AUTOSAR XML (schema 00047)
package /LIN2
  n pdu NPdu_LIN2_MasterReq
  n pdu NPdu_LIN2_SlaveResp
package /LIN2/CLUSTERS
  lin cluster LIN2: protocol-version="2.1", speed=19200
    lin physical channel PhysicalChannel_0: comm-connectors=Conn_ECU1_LIN2
      frame LinUnconditionalFrame_LIN2_Master_Cmd: id 0x8, frame-length=5
        pdu ISignalIPdu_LIN2_Master_Cmd: length=5
          signal ISignal_LIN2_Master_Cmd_NAD: start 0, 8 bit, little-endian, init-value=255
          signal ISignal_LIN2_Master_Cmd_PCI_Type: start 8, 8 bit, little-endian, init-value=3
          signal ISignal_LIN2_Master_Cmd_SID: start 16, 8 bit, little-endian, init-value=0
          signal ISignal_LIN2_Master_Cmd_RL_Sensor_Tx: start 24, 1 bit, little-endian, init-value=0
          signal ISignal_LIN2_Master_Cmd_RCL_Sensor_Tx: start 25, 1 bit, little-endian, init-value=0
          signal ISignal_LIN2_Master_Cmd_RCR_Sensor_Tx: start 26, 1 bit, little-endian, init-value=0
          signal ISignal_LIN2_Master_Cmd_RR_Sensor_Tx: start 27, 1 bit, little-endian, init-value=0
          signal ISignal_LIN2_Master_Cmd_FL_Sensor_Tx: start 28, 1 bit, little-endian, init-value=0
          signal ISignal_LIN2_Master_Cmd_FCL_Sensor_Tx: start 29, 1 bit, little-endian, init-value=0
          signal ISignal_LIN2_Master_Cmd_FCR_Sensor_Tx: start 30, 1 bit, little-endian, init-value=0
          signal ISignal_LIN2_Master_Cmd_FR_Sensor_Tx: start 31, 1 bit, little-endian, init-value=0
          signal ISignal_LIN2_Master_Cmd_RL_Sensor_Rx: start 32, 1 bit, little-endian, init-value=0
          signal ISignal_LIN2_Master_Cmd_RCL_Sensor_Rx: start 33, 1 bit, little-endian, init-value=0
          signal ISignal_LIN2_Master_Cmd_RCR_Sensor_Rx: start 34, 1 bit, little-endian, init-value=0
          signal ISignal_LIN2_Master_Cmd_RR_Sensor_Rx: start 35, 1 bit, little-endian, init-value=0
          signal ISignal_LIN2_Master_Cmd_FL_Sensor_Rx: start 36, 1 bit, little-endian, init-value=0
          signal ISignal_LIN2_Master_Cmd_FCL_Sensor_Rx: start 37, 1 bit, little-endian, init-value=0
          signal ISignal_LIN2_Master_Cmd_FCR_Sensor_Rx: start 38, 1 bit, little-endian, init-value=0
          signal ISignal_LIN2_Master_Cmd_FR_Sensor_Rx: start 39, 1 bit, little-endian, init-value=0
          mapping SigGrp_LIN2_Master_Cmd: i-signal-group=MsgGr_LIN2_Master_Cmd
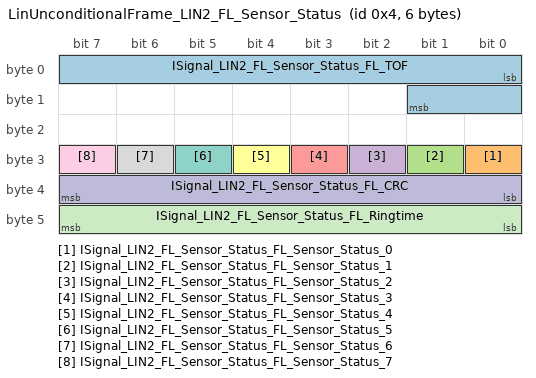
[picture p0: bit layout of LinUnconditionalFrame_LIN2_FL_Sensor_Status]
      frame LinUnconditionalFrame_LIN2_FL_Sensor_Status: id 0x4, frame-length=6
        pdu ISignalIPdu_LIN2_FL_Sensor_Status: length=6
          signal ISignal_LIN2_FL_Sensor_Status_FL_TOF: start 0, 10 bit, little-endian, init-value=0
          signal ISignal_LIN2_FL_Sensor_Status_FL_Sensor_Status_0: start 24, 1 bit, little-endian, init-value=0
          signal ISignal_LIN2_FL_Sensor_Status_FL_Sensor_Status_1: start 25, 1 bit, little-endian, init-value=0
          signal ISignal_LIN2_FL_Sensor_Status_FL_Sensor_Status_2: start 26, 1 bit, little-endian, init-value=0
          signal ISignal_LIN2_FL_Sensor_Status_FL_Sensor_Status_3: start 27, 1 bit, little-endian, init-value=0
          signal ISignal_LIN2_FL_Sensor_Status_FL_Sensor_Status_4: start 28, 1 bit, little-endian, init-value=0
          signal ISignal_LIN2_FL_Sensor_Status_FL_Sensor_Status_5: start 29, 1 bit, little-endian, init-value=0
          signal ISignal_LIN2_FL_Sensor_Status_FL_Sensor_Status_6: start 30, 1 bit, little-endian, init-value=0
          signal ISignal_LIN2_FL_Sensor_Status_FL_Sensor_Status_7: start 31, 1 bit, little-endian, init-value=0
          signal ISignal_LIN2_FL_Sensor_Status_FL_CRC: start 32, 8 bit, little-endian, init-value=0
          signal ISignal_LIN2_FL_Sensor_Status_FL_Ringtime: start 40, 8 bit, little-endian, init-value=0
          mapping SigGrp_LIN2_FL_Sensor_Status: i-signal-group=MsgGr_LIN2_FL_Sensor_Status
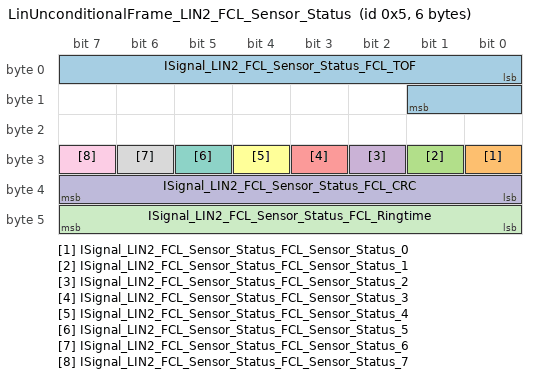
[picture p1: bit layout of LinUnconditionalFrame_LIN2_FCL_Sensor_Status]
      frame LinUnconditionalFrame_LIN2_FCL_Sensor_Status: id 0x5, frame-length=6
        pdu ISignalIPdu_LIN2_FCL_Sensor_Status: length=6
          signal ISignal_LIN2_FCL_Sensor_Status_FCL_TOF: start 0, 10 bit, little-endian, init-value=0
          signal ISignal_LIN2_FCL_Sensor_Status_FCL_Sensor_Status_0: start 24, 1 bit, little-endian, init-value=0
          signal ISignal_LIN2_FCL_Sensor_Status_FCL_Sensor_Status_1: start 25, 1 bit, little-endian, init-value=0
          signal ISignal_LIN2_FCL_Sensor_Status_FCL_Sensor_Status_2: start 26, 1 bit, little-endian, init-value=0
          signal ISignal_LIN2_FCL_Sensor_Status_FCL_Sensor_Status_3: start 27, 1 bit, little-endian, init-value=0
          signal ISignal_LIN2_FCL_Sensor_Status_FCL_Sensor_Status_4: start 28, 1 bit, little-endian, init-value=0
          signal ISignal_LIN2_FCL_Sensor_Status_FCL_Sensor_Status_5: start 29, 1 bit, little-endian, init-value=0
          signal ISignal_LIN2_FCL_Sensor_Status_FCL_Sensor_Status_6: start 30, 1 bit, little-endian, init-value=0
          signal ISignal_LIN2_FCL_Sensor_Status_FCL_Sensor_Status_7: start 31, 1 bit, little-endian, init-value=0
          signal ISignal_LIN2_FCL_Sensor_Status_FCL_CRC: start 32, 8 bit, little-endian, init-value=0
          signal ISignal_LIN2_FCL_Sensor_Status_FCL_Ringtime: start 40, 8 bit, little-endian, init-value=0
          mapping SigGrp_LIN2_FCL_Sensor_Status: i-signal-group=MsgGr_LIN2_FCL_Sensor_Status
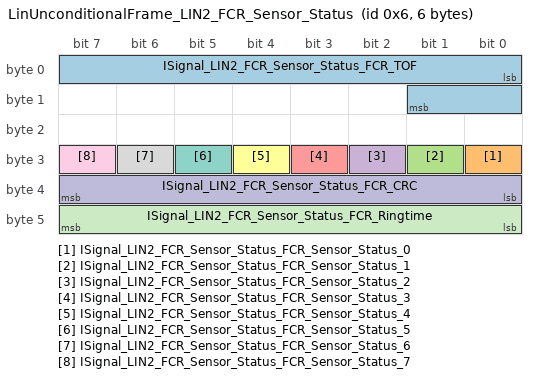
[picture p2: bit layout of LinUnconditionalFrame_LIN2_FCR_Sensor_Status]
      frame LinUnconditionalFrame_LIN2_FCR_Sensor_Status: id 0x6, frame-length=6
        pdu ISignalIPdu_LIN2_FCR_Sensor_Status: length=6
          signal ISignal_LIN2_FCR_Sensor_Status_FCR_TOF: start 0, 10 bit, little-endian, init-value=0
          signal ISignal_LIN2_FCR_Sensor_Status_FCR_Sensor_Status_0: start 24, 1 bit, little-endian, init-value=0
          signal ISignal_LIN2_FCR_Sensor_Status_FCR_Sensor_Status_1: start 25, 1 bit, little-endian, init-value=0
          signal ISignal_LIN2_FCR_Sensor_Status_FCR_Sensor_Status_2: start 26, 1 bit, little-endian, init-value=0
          signal ISignal_LIN2_FCR_Sensor_Status_FCR_Sensor_Status_3: start 27, 1 bit, little-endian, init-value=0
          signal ISignal_LIN2_FCR_Sensor_Status_FCR_Sensor_Status_4: start 28, 1 bit, little-endian, init-value=0
          signal ISignal_LIN2_FCR_Sensor_Status_FCR_Sensor_Status_5: start 29, 1 bit, little-endian, init-value=0
          signal ISignal_LIN2_FCR_Sensor_Status_FCR_Sensor_Status_6: start 30, 1 bit, little-endian, init-value=0
          signal ISignal_LIN2_FCR_Sensor_Status_FCR_Sensor_Status_7: start 31, 1 bit, little-endian, init-value=0
          signal ISignal_LIN2_FCR_Sensor_Status_FCR_CRC: start 32, 8 bit, little-endian, init-value=0
          signal ISignal_LIN2_FCR_Sensor_Status_FCR_Ringtime: start 40, 8 bit, little-endian, init-value=0
          mapping SigGrp_LIN2_FCR_Sensor_Status: i-signal-group=MsgGr_LIN2_FCR_Sensor_Status
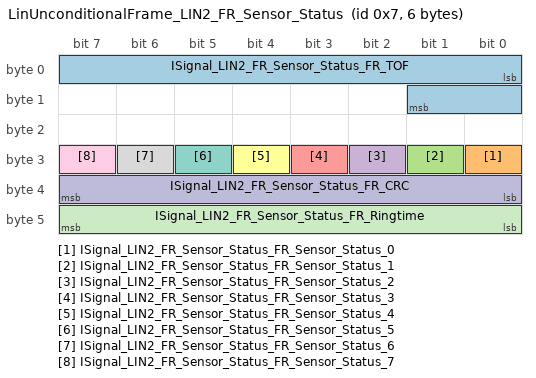
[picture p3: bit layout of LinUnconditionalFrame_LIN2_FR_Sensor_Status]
      frame LinUnconditionalFrame_LIN2_FR_Sensor_Status: id 0x7, frame-length=6
        pdu ISignalIPdu_LIN2_FR_Sensor_Status: length=6
          signal ISignal_LIN2_FR_Sensor_Status_FR_TOF: start 0, 10 bit, little-endian, init-value=0
          signal ISignal_LIN2_FR_Sensor_Status_FR_Sensor_Status_0: start 24, 1 bit, little-endian, init-value=0
          signal ISignal_LIN2_FR_Sensor_Status_FR_Sensor_Status_1: start 25, 1 bit, little-endian, init-value=0
          signal ISignal_LIN2_FR_Sensor_Status_FR_Sensor_Status_2: start 26, 1 bit, little-endian, init-value=0
          signal ISignal_LIN2_FR_Sensor_Status_FR_Sensor_Status_3: start 27, 1 bit, little-endian, init-value=0
          signal ISignal_LIN2_FR_Sensor_Status_FR_Sensor_Status_4: start 28, 1 bit, little-endian, init-value=0
          signal ISignal_LIN2_FR_Sensor_Status_FR_Sensor_Status_5: start 29, 1 bit, little-endian, init-value=0
          signal ISignal_LIN2_FR_Sensor_Status_FR_Sensor_Status_6: start 30, 1 bit, little-endian, init-value=0
          signal ISignal_LIN2_FR_Sensor_Status_FR_Sensor_Status_7: start 31, 1 bit, little-endian, init-value=0
          signal ISignal_LIN2_FR_Sensor_Status_FR_CRC: start 32, 8 bit, little-endian, init-value=0
          signal ISignal_LIN2_FR_Sensor_Status_FR_Ringtime: start 40, 8 bit, little-endian, init-value=0
          mapping SigGrp_LIN2_FR_Sensor_Status: i-signal-group=MsgGr_LIN2_FR_Sensor_Status
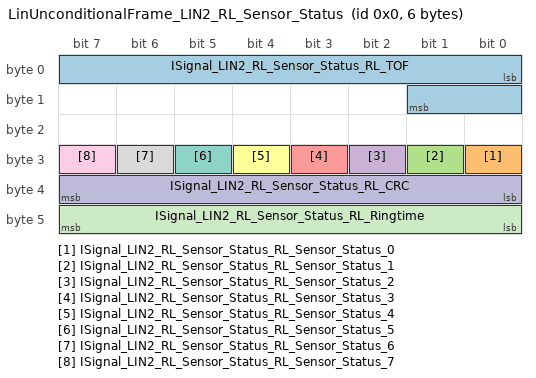
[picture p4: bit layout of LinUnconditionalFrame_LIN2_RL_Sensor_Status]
      frame LinUnconditionalFrame_LIN2_RL_Sensor_Status: id 0x0, frame-length=6
        pdu ISignalIPdu_LIN2_RL_Sensor_Status: length=6
          signal ISignal_LIN2_RL_Sensor_Status_RL_TOF: start 0, 10 bit, little-endian, init-value=0
          signal ISignal_LIN2_RL_Sensor_Status_RL_Sensor_Status_0: start 24, 1 bit, little-endian, init-value=0
          signal ISignal_LIN2_RL_Sensor_Status_RL_Sensor_Status_1: start 25, 1 bit, little-endian, init-value=0
          signal ISignal_LIN2_RL_Sensor_Status_RL_Sensor_Status_2: start 26, 1 bit, little-endian, init-value=0
          signal ISignal_LIN2_RL_Sensor_Status_RL_Sensor_Status_3: start 27, 1 bit, little-endian, init-value=0
          signal ISignal_LIN2_RL_Sensor_Status_RL_Sensor_Status_4: start 28, 1 bit, little-endian, init-value=0
          signal ISignal_LIN2_RL_Sensor_Status_RL_Sensor_Status_5: start 29, 1 bit, little-endian, init-value=0
          signal ISignal_LIN2_RL_Sensor_Status_RL_Sensor_Status_6: start 30, 1 bit, little-endian, init-value=0
          signal ISignal_LIN2_RL_Sensor_Status_RL_Sensor_Status_7: start 31, 1 bit, little-endian, init-value=0
          signal ISignal_LIN2_RL_Sensor_Status_RL_CRC: start 32, 8 bit, little-endian, init-value=0
          signal ISignal_LIN2_RL_Sensor_Status_RL_Ringtime: start 40, 8 bit, little-endian, init-value=0
          mapping SigGrp_LIN2_RL_Sensor_Status: i-signal-group=MsgGr_LIN2_RL_Sensor_Status
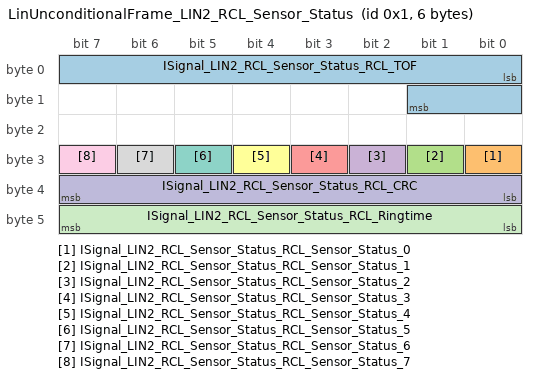
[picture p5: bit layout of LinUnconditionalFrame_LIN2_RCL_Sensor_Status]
      frame LinUnconditionalFrame_LIN2_RCL_Sensor_Status: id 0x1, frame-length=6
        pdu ISignalIPdu_LIN2_RCL_Sensor_Status: length=6
          signal ISignal_LIN2_RCL_Sensor_Status_RCL_TOF: start 0, 10 bit, little-endian, init-value=0
          signal ISignal_LIN2_RCL_Sensor_Status_RCL_Sensor_Status_0: start 24, 1 bit, little-endian, init-value=0
          signal ISignal_LIN2_RCL_Sensor_Status_RCL_Sensor_Status_1: start 25, 1 bit, little-endian, init-value=0
          signal ISignal_LIN2_RCL_Sensor_Status_RCL_Sensor_Status_2: start 26, 1 bit, little-endian, init-value=0
          signal ISignal_LIN2_RCL_Sensor_Status_RCL_Sensor_Status_3: start 27, 1 bit, little-endian, init-value=0
          signal ISignal_LIN2_RCL_Sensor_Status_RCL_Sensor_Status_4: start 28, 1 bit, little-endian, init-value=0
          signal ISignal_LIN2_RCL_Sensor_Status_RCL_Sensor_Status_5: start 29, 1 bit, little-endian, init-value=0
          signal ISignal_LIN2_RCL_Sensor_Status_RCL_Sensor_Status_6: start 30, 1 bit, little-endian, init-value=0
          signal ISignal_LIN2_RCL_Sensor_Status_RCL_Sensor_Status_7: start 31, 1 bit, little-endian, init-value=0
          signal ISignal_LIN2_RCL_Sensor_Status_RCL_CRC: start 32, 8 bit, little-endian, init-value=0
          signal ISignal_LIN2_RCL_Sensor_Status_RCL_Ringtime: start 40, 8 bit, little-endian, init-value=0
          mapping SigGrp_LIN2_RCL_Sensor_Status: i-signal-group=MsgGr_LIN2_RCL_Sensor_Status
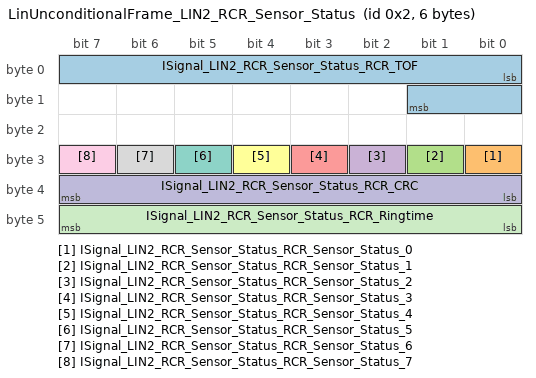
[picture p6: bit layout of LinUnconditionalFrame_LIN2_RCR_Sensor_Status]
      frame LinUnconditionalFrame_LIN2_RCR_Sensor_Status: id 0x2, frame-length=6
        pdu ISignalIPdu_LIN2_RCR_Sensor_Status: length=6
          signal ISignal_LIN2_RCR_Sensor_Status_RCR_TOF: start 0, 10 bit, little-endian, init-value=0
          signal ISignal_LIN2_RCR_Sensor_Status_RCR_Sensor_Status_0: start 24, 1 bit, little-endian, init-value=0
          signal ISignal_LIN2_RCR_Sensor_Status_RCR_Sensor_Status_1: start 25, 1 bit, little-endian, init-value=0
          signal ISignal_LIN2_RCR_Sensor_Status_RCR_Sensor_Status_2: start 26, 1 bit, little-endian, init-value=0
          signal ISignal_LIN2_RCR_Sensor_Status_RCR_Sensor_Status_3: start 27, 1 bit, little-endian, init-value=0
          signal ISignal_LIN2_RCR_Sensor_Status_RCR_Sensor_Status_4: start 28, 1 bit, little-endian, init-value=0
          signal ISignal_LIN2_RCR_Sensor_Status_RCR_Sensor_Status_5: start 29, 1 bit, little-endian, init-value=0
          signal ISignal_LIN2_RCR_Sensor_Status_RCR_Sensor_Status_6: start 30, 1 bit, little-endian, init-value=0
          signal ISignal_LIN2_RCR_Sensor_Status_RCR_Sensor_Status_7: start 31, 1 bit, little-endian, init-value=0
          signal ISignal_LIN2_RCR_Sensor_Status_RCR_CRC: start 32, 8 bit, little-endian, init-value=0
          signal ISignal_LIN2_RCR_Sensor_Status_RCR_Ringtime: start 40, 8 bit, little-endian, init-value=0
          mapping SigGrp_LIN2_RCR_Sensor_Status: i-signal-group=MsgGr_LIN2_RCR_Sensor_Status
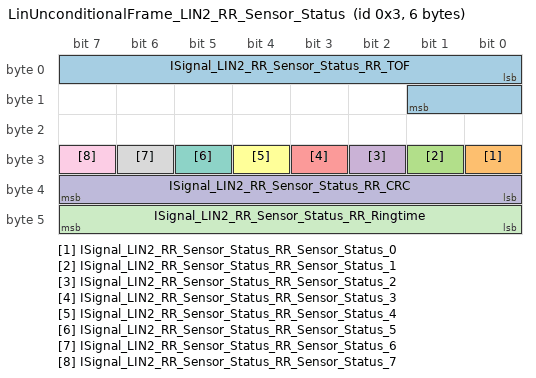
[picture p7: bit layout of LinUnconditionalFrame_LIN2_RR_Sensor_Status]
      frame LinUnconditionalFrame_LIN2_RR_Sensor_Status: id 0x3, frame-length=6
        pdu ISignalIPdu_LIN2_RR_Sensor_Status: length=6
          signal ISignal_LIN2_RR_Sensor_Status_RR_TOF: start 0, 10 bit, little-endian, init-value=0
          signal ISignal_LIN2_RR_Sensor_Status_RR_Sensor_Status_0: start 24, 1 bit, little-endian, init-value=0
          signal ISignal_LIN2_RR_Sensor_Status_RR_Sensor_Status_1: start 25, 1 bit, little-endian, init-value=0
          signal ISignal_LIN2_RR_Sensor_Status_RR_Sensor_Status_2: start 26, 1 bit, little-endian, init-value=0
          signal ISignal_LIN2_RR_Sensor_Status_RR_Sensor_Status_3: start 27, 1 bit, little-endian, init-value=0
          signal ISignal_LIN2_RR_Sensor_Status_RR_Sensor_Status_4: start 28, 1 bit, little-endian, init-value=0
          signal ISignal_LIN2_RR_Sensor_Status_RR_Sensor_Status_5: start 29, 1 bit, little-endian, init-value=0
          signal ISignal_LIN2_RR_Sensor_Status_RR_Sensor_Status_6: start 30, 1 bit, little-endian, init-value=0
          signal ISignal_LIN2_RR_Sensor_Status_RR_Sensor_Status_7: start 31, 1 bit, little-endian, init-value=0
          signal ISignal_LIN2_RR_Sensor_Status_RR_CRC: start 32, 8 bit, little-endian, init-value=0
          signal ISignal_LIN2_RR_Sensor_Status_RR_Ringtime: start 40, 8 bit, little-endian, init-value=0
          mapping SigGrp_LIN2_RR_Sensor_Status: i-signal-group=MsgGr_LIN2_RR_Sensor_Status
      frame LinUnconditionalFrame_LIN2_MasterReq: id 0x3C, frame-length=8, lin-checksum=CLASSIC
        dcm i pdu DcmIPdu_LIN2_MasterReq: length=8, diag-pdu-type=DIAG-REQUEST
      frame LinUnconditionalFrame_LIN2_SlaveResp: id 0x3D, frame-length=8, lin-checksum=CLASSIC
        dcm i pdu DcmIPdu_LIN2_SlaveResp: length=8, diag-pdu-type=DIAG-RESPONSE
      22 x lin schedule table, all with run-mode=RUN-CONTINUOUS:
        LinScheduleTable_SCHEDULER_RPAS_NORMAL
          table-entrys:
            delay=0.08, position-in-table=0, frame-triggering=LinFrameTriggering_LIN2_Master_Cmd
            delay=0.01, position-in-table=1, frame-triggering=LinFrameTriggering_LIN2_RL_Sensor_Status
            delay=0.08, position-in-table=2, frame-triggering=LinFrameTriggering_LIN2_Master_Cmd
            delay=0.01, position-in-table=3, frame-triggering=LinFrameTriggering_LIN2_RR_Sensor_Status
            delay=0.08, position-in-table=4, frame-triggering=LinFrameTriggering_LIN2_Master_Cmd
            delay=0.01, position-in-table=5, frame-triggering=LinFrameTriggering_LIN2_RL_Sensor_Status
            delay=0.01, position-in-table=6, frame-triggering=LinFrameTriggering_LIN2_RCL_Sensor_Status
            delay=0.01, position-in-table=7, frame-triggering=LinFrameTriggering_LIN2_RCR_Sensor_Status
            delay=0.08, position-in-table=8, frame-triggering=LinFrameTriggering_LIN2_Master_Cmd
            delay=0.01, position-in-table=9, frame-triggering=LinFrameTriggering_LIN2_RCL_Sensor_Status
            delay=0.01, position-in-table=10, frame-triggering=LinFrameTriggering_LIN2_RCR_Sensor_Status
            delay=0.01, position-in-table=11, frame-triggering=LinFrameTriggering_LIN2_RR_Sensor_Status
        LinScheduleTable_SCHEDULER_RPAS_CRC_COMPARE
          table-entrys:
            delay=0.02, position-in-table=0, frame-triggering=LinFrameTriggering_LIN2_Master_Cmd
            delay=0.01, position-in-table=1, frame-triggering=LinFrameTriggering_LIN2_RL_Sensor_Status
            delay=0.01, position-in-table=2, frame-triggering=LinFrameTriggering_LIN2_RCL_Sensor_Status
            delay=0.01, position-in-table=3, frame-triggering=LinFrameTriggering_LIN2_RCR_Sensor_Status
            delay=0.01, position-in-table=4, frame-triggering=LinFrameTriggering_LIN2_RR_Sensor_Status
        LinScheduleTable_SCHEDULER_PAS_NORMAL
          table-entrys:
            delay=0.08, position-in-table=0, frame-triggering=LinFrameTriggering_LIN2_Master_Cmd
            delay=0.01, position-in-table=1, frame-triggering=LinFrameTriggering_LIN2_RL_Sensor_Status
            delay=0.01, position-in-table=2, frame-triggering=LinFrameTriggering_LIN2_FR_Sensor_Status
            delay=0.08, position-in-table=3, frame-triggering=LinFrameTriggering_LIN2_Master_Cmd
            delay=0.01, position-in-table=4, frame-triggering=LinFrameTriggering_LIN2_RR_Sensor_Status
            delay=0.01, position-in-table=5, frame-triggering=LinFrameTriggering_LIN2_FL_Sensor_Status
            delay=0.08, position-in-table=6, frame-triggering=LinFrameTriggering_LIN2_Master_Cmd
            delay=0.01, position-in-table=7, frame-triggering=LinFrameTriggering_LIN2_RL_Sensor_Status
            delay=0.01, position-in-table=8, frame-triggering=LinFrameTriggering_LIN2_RCL_Sensor_Status
            delay=0.01, position-in-table=9, frame-triggering=LinFrameTriggering_LIN2_RCR_Sensor_Status
            delay=0.08, position-in-table=10, frame-triggering=LinFrameTriggering_LIN2_Master_Cmd
            delay=0.01, position-in-table=11, frame-triggering=LinFrameTriggering_LIN2_RCL_Sensor_Status
            delay=0.01, position-in-table=12, frame-triggering=LinFrameTriggering_LIN2_RCR_Sensor_Status
            delay=0.01, position-in-table=13, frame-triggering=LinFrameTriggering_LIN2_RR_Sensor_Status
        LinScheduleTable_SCHEDULER_PAS_CRC_COMPARE
          table-entrys:
            delay=0.02, position-in-table=0, frame-triggering=LinFrameTriggering_LIN2_Master_Cmd
            delay=0.01, position-in-table=1, frame-triggering=LinFrameTriggering_LIN2_RL_Sensor_Status
            delay=0.01, position-in-table=2, frame-triggering=LinFrameTriggering_LIN2_RCL_Sensor_Status
            delay=0.01, position-in-table=3, frame-triggering=LinFrameTriggering_LIN2_RCR_Sensor_Status
            delay=0.01, position-in-table=4, frame-triggering=LinFrameTriggering_LIN2_RR_Sensor_Status
            delay=0.01, position-in-table=5, frame-triggering=LinFrameTriggering_LIN2_FL_Sensor_Status
            delay=0.01, position-in-table=6, frame-triggering=LinFrameTriggering_LIN2_FCL_Sensor_Status
            delay=0.01, position-in-table=7, frame-triggering=LinFrameTriggering_LIN2_FCR_Sensor_Status
            delay=0.01, position-in-table=8, frame-triggering=LinFrameTriggering_LIN2_FR_Sensor_Status
        LinScheduleTable_SCHEDULER_FRONT_PAS_NORMAL
          table-entrys:
            delay=0.08, position-in-table=0, frame-triggering=LinFrameTriggering_LIN2_Master_Cmd
            delay=0.01, position-in-table=1, frame-triggering=LinFrameTriggering_LIN2_FL_Sensor_Status
            delay=0.08, position-in-table=2, frame-triggering=LinFrameTriggering_LIN2_Master_Cmd
            delay=0.01, position-in-table=3, frame-triggering=LinFrameTriggering_LIN2_FR_Sensor_Status
            delay=0.08, position-in-table=4, frame-triggering=LinFrameTriggering_LIN2_Master_Cmd
            delay=0.01, position-in-table=5, frame-triggering=LinFrameTriggering_LIN2_FL_Sensor_Status
            delay=0.01, position-in-table=6, frame-triggering=LinFrameTriggering_LIN2_FCL_Sensor_Status
            delay=0.01, position-in-table=7, frame-triggering=LinFrameTriggering_LIN2_FCR_Sensor_Status
            delay=0.08, position-in-table=8, frame-triggering=LinFrameTriggering_LIN2_Master_Cmd
            delay=0.01, position-in-table=9, frame-triggering=LinFrameTriggering_LIN2_FCL_Sensor_Status
            delay=0.01, position-in-table=10, frame-triggering=LinFrameTriggering_LIN2_FCR_Sensor_Status
            delay=0.01, position-in-table=11, frame-triggering=LinFrameTriggering_LIN2_FR_Sensor_Status
        LinScheduleTable_SCHEDULER_PAS_DIAG_IBU: application-entry{delay=0.01, position-in-table=0, frame-triggering=LinFrameTriggering_LIN2_Master_Cmd}
        LinScheduleTable_SCHEDULER_PAS_DIAG_FL: application-entry{delay=0.01, position-in-table=0, frame-triggering=LinFrameTriggering_LIN2_FL_Sensor_Status}
        LinScheduleTable_SCHEDULER_PAS_DIAG_FCL: application-entry{delay=0.01, position-in-table=0, frame-triggering=LinFrameTriggering_LIN2_FCL_Sensor_Status}
        LinScheduleTable_SCHEDULER_PAS_DIAG_FCR: application-entry{delay=0.01, position-in-table=0, frame-triggering=LinFrameTriggering_LIN2_FCR_Sensor_Status}
        LinScheduleTable_SCHEDULER_PAS_DIAG_FR: application-entry{delay=0.01, position-in-table=0, frame-triggering=LinFrameTriggering_LIN2_FR_Sensor_Status}
        LinScheduleTable_SCHEDULER_PAS_DIAG_RL: application-entry{delay=0.01, position-in-table=0, frame-triggering=LinFrameTriggering_LIN2_RL_Sensor_Status}
        LinScheduleTable_SCHEDULER_PAS_DIAG_RCL: application-entry{delay=0.01, position-in-table=0, frame-triggering=LinFrameTriggering_LIN2_RCL_Sensor_Status}
        LinScheduleTable_SCHEDULER_PAS_DIAG_RCR: application-entry{delay=0.01, position-in-table=0, frame-triggering=LinFrameTriggering_LIN2_RCR_Sensor_Status}
        LinScheduleTable_SCHEDULER_PAS_DIAG_RR: application-entry{delay=0.01, position-in-table=0, frame-triggering=LinFrameTriggering_LIN2_RR_Sensor_Status}
        LinScheduleTable_SCHEDULER_RPAS_VER_CHECK
          table-entrys:
            delay=0.015, position-in-table=0, frame-triggering=LinFrameTriggering_LIN2_MasterReq
            delay=0.015, position-in-table=1, frame-triggering=LinFrameTriggering_LIN2_SlaveResp
            delay=0.015, position-in-table=2, frame-triggering=LinFrameTriggering_LIN2_MasterReq
            delay=0.015, position-in-table=3, frame-triggering=LinFrameTriggering_LIN2_SlaveResp
            delay=0.015, position-in-table=4, frame-triggering=LinFrameTriggering_LIN2_MasterReq
            delay=0.015, position-in-table=5, frame-triggering=LinFrameTriggering_LIN2_SlaveResp
            delay=0.015, position-in-table=6, frame-triggering=LinFrameTriggering_LIN2_MasterReq
            delay=0.015, position-in-table=7, frame-triggering=LinFrameTriggering_LIN2_SlaveResp
        LinScheduleTable_SCHEDULER_FPAS_VER_CHECK
          table-entrys:
            delay=0.015, position-in-table=0, frame-triggering=LinFrameTriggering_LIN2_MasterReq
            delay=0.015, position-in-table=1, frame-triggering=LinFrameTriggering_LIN2_SlaveResp
            delay=0.015, position-in-table=2, frame-triggering=LinFrameTriggering_LIN2_MasterReq
            delay=0.015, position-in-table=3, frame-triggering=LinFrameTriggering_LIN2_SlaveResp
            delay=0.015, position-in-table=4, frame-triggering=LinFrameTriggering_LIN2_MasterReq
            delay=0.015, position-in-table=5, frame-triggering=LinFrameTriggering_LIN2_SlaveResp
            delay=0.015, position-in-table=6, frame-triggering=LinFrameTriggering_LIN2_MasterReq
            delay=0.015, position-in-table=7, frame-triggering=LinFrameTriggering_LIN2_SlaveResp
            delay=0.015, position-in-table=8, frame-triggering=LinFrameTriggering_LIN2_MasterReq
            delay=0.015, position-in-table=9, frame-triggering=LinFrameTriggering_LIN2_SlaveResp
            delay=0.015, position-in-table=10, frame-triggering=LinFrameTriggering_LIN2_MasterReq
            delay=0.015, position-in-table=11, frame-triggering=LinFrameTriggering_LIN2_SlaveResp
            delay=0.015, position-in-table=12, frame-triggering=LinFrameTriggering_LIN2_MasterReq
            delay=0.015, position-in-table=13, frame-triggering=LinFrameTriggering_LIN2_SlaveResp
            delay=0.015, position-in-table=14, frame-triggering=LinFrameTriggering_LIN2_MasterReq
            delay=0.015, position-in-table=15, frame-triggering=LinFrameTriggering_LIN2_SlaveResp
            delay=0.015, position-in-table=16, frame-triggering=LinFrameTriggering_LIN2_MasterReq
            delay=0.015, position-in-table=17, frame-triggering=LinFrameTriggering_LIN2_SlaveResp
            delay=0.015, position-in-table=18, frame-triggering=LinFrameTriggering_LIN2_MasterReq
            delay=0.015, position-in-table=19, frame-triggering=LinFrameTriggering_LIN2_SlaveResp
            delay=0.015, position-in-table=20, frame-triggering=LinFrameTriggering_LIN2_MasterReq
            delay=0.015, position-in-table=21, frame-triggering=LinFrameTriggering_LIN2_SlaveResp
            delay=0.015, position-in-table=22, frame-triggering=LinFrameTriggering_LIN2_MasterReq
            delay=0.015, position-in-table=23, frame-triggering=LinFrameTriggering_LIN2_SlaveResp
            delay=0.015, position-in-table=24, frame-triggering=LinFrameTriggering_LIN2_MasterReq
            delay=0.015, position-in-table=25, frame-triggering=LinFrameTriggering_LIN2_SlaveResp
            delay=0.015, position-in-table=26, frame-triggering=LinFrameTriggering_LIN2_MasterReq
            delay=0.015, position-in-table=27, frame-triggering=LinFrameTriggering_LIN2_SlaveResp
            delay=0.015, position-in-table=28, frame-triggering=LinFrameTriggering_LIN2_MasterReq
            delay=0.015, position-in-table=29, frame-triggering=LinFrameTriggering_LIN2_SlaveResp
            delay=0.015, position-in-table=30, frame-triggering=LinFrameTriggering_LIN2_MasterReq
            delay=0.015, position-in-table=31, frame-triggering=LinFrameTriggering_LIN2_SlaveResp
        LinScheduleTable_SCHEDULER_RPAS_TUNNING_WRITE
          table-entrys:
            delay=0.015, position-in-table={0..15}, frame-triggering=LinFrameTriggering_LIN2_MasterReq
        LinScheduleTable_SCHEDULER_RPAS_TEMP_COMP
          table-entrys:
            delay=0.015, position-in-table={0..3}, frame-triggering=LinFrameTriggering_LIN2_MasterReq
        LinScheduleTable_SCHEDULER_FPAS_TUNNING_WRITE
          table-entrys:
            delay=0.015, position-in-table={0..31}, frame-triggering=LinFrameTriggering_LIN2_MasterReq
        LinScheduleTable_SCHEDULER_PAS_TEMP_COMP
          table-entrys:
            delay=0.015, position-in-table={0..7}, frame-triggering=LinFrameTriggering_LIN2_MasterReq
        LinScheduleTable_SCHEDULER_PAS_DIAG
          table-entrys:
            delay=0.015, position-in-table=0, frame-triggering=LinFrameTriggering_LIN2_MasterReq
            delay=0.015, position-in-table=1, frame-triggering=LinFrameTriggering_LIN2_SlaveResp
        LinScheduleTable_SCHEDULER_PAS_SENSOR_REQUEST: application-entry{delay=0.015, position-in-table=0, frame-triggering=LinFrameTriggering_LIN2_MasterReq}
package /LIN2/IPDUGROUPS
  i signal i pdu group ISignalIPduGroupTx_ECU1_LIN2: communication-direction=OUT, i-signal-i-pdus=ISignalIPdu_LIN2_Master_Cmd
  i signal i pdu group ISignalIPduGroupRx_ECU1_LIN2: communication-direction=IN
    i-signal-i-pdus:
      ISignalIPdu_LIN2_FL_Sensor_Status
      ISignalIPdu_LIN2_FCL_Sensor_Status
      ISignalIPdu_LIN2_FCR_Sensor_Status
      ISignalIPdu_LIN2_FR_Sensor_Status
      ISignalIPdu_LIN2_RL_Sensor_Status
      ISignalIPdu_LIN2_RCL_Sensor_Status
      ISignalIPdu_LIN2_RCR_Sensor_Status
      ISignalIPdu_LIN2_RR_Sensor_Status
package /LIN2/ImplementationDataTypes
  11 x impl type, all with category=STRUCTURE:
    MsgGr_LIN2_Master_Cmd
      19 x element, all with category=TYPE_REFERENCE:
        NAD: implementation-data-type=uint8
        PCI_Type: implementation-data-type=uint8
        SID: implementation-data-type=uint8
        RL_Sensor_Tx: implementation-data-type=boolean
        RCL_Sensor_Tx: implementation-data-type=boolean
        RCR_Sensor_Tx: implementation-data-type=boolean
        RR_Sensor_Tx: implementation-data-type=boolean
        FL_Sensor_Tx: implementation-data-type=boolean
        FCL_Sensor_Tx: implementation-data-type=boolean
        FCR_Sensor_Tx: implementation-data-type=boolean
        FR_Sensor_Tx: implementation-data-type=boolean
        RL_Sensor_Rx: implementation-data-type=boolean
        RCL_Sensor_Rx: implementation-data-type=boolean
        RCR_Sensor_Rx: implementation-data-type=boolean
        RR_Sensor_Rx: implementation-data-type=boolean
        FL_Sensor_Rx: implementation-data-type=boolean
        FCL_Sensor_Rx: implementation-data-type=boolean
        FCR_Sensor_Rx: implementation-data-type=boolean
        FR_Sensor_Rx: implementation-data-type=boolean
    MsgGr_LIN2_FL_Sensor_Status
      11 x element, all with category=TYPE_REFERENCE:
        FL_TOF: implementation-data-type=uint16
        FL_Sensor_Status_{0..7}: implementation-data-type=boolean
        FL_CRC: implementation-data-type=uint8
        FL_Ringtime: implementation-data-type=uint8
    MsgGr_LIN2_FCL_Sensor_Status
      11 x element, all with category=TYPE_REFERENCE:
        FCL_TOF: implementation-data-type=uint16
        FCL_Sensor_Status_{0..7}: implementation-data-type=boolean
        FCL_CRC: implementation-data-type=uint8
        FCL_Ringtime: implementation-data-type=uint8
    MsgGr_LIN2_FCR_Sensor_Status
      11 x element, all with category=TYPE_REFERENCE:
        FCR_TOF: implementation-data-type=uint16
        FCR_Sensor_Status_{0..7}: implementation-data-type=boolean
        FCR_CRC: implementation-data-type=uint8
        FCR_Ringtime: implementation-data-type=uint8
    MsgGr_LIN2_FR_Sensor_Status
      11 x element, all with category=TYPE_REFERENCE:
        FR_TOF: implementation-data-type=uint16
        FR_Sensor_Status_{0..7}: implementation-data-type=boolean
        FR_CRC: implementation-data-type=uint8
        FR_Ringtime: implementation-data-type=uint8
    MsgGr_LIN2_RL_Sensor_Status
      11 x element, all with category=TYPE_REFERENCE:
        RL_TOF: implementation-data-type=uint16
        RL_Sensor_Status_{0..7}: implementation-data-type=boolean
        RL_CRC: implementation-data-type=uint8
        RL_Ringtime: implementation-data-type=uint8
    MsgGr_LIN2_RCL_Sensor_Status
      11 x element, all with category=TYPE_REFERENCE:
        RCL_TOF: implementation-data-type=uint16
        RCL_Sensor_Status_{0..7}: implementation-data-type=boolean
        RCL_CRC: implementation-data-type=uint8
        RCL_Ringtime: implementation-data-type=uint8
    MsgGr_LIN2_RCR_Sensor_Status
      11 x element, all with category=TYPE_REFERENCE:
        RCR_TOF: implementation-data-type=uint16
        RCR_Sensor_Status_{0..7}: implementation-data-type=boolean
        RCR_CRC: implementation-data-type=uint8
        RCR_Ringtime: implementation-data-type=uint8
    MsgGr_LIN2_RR_Sensor_Status
      11 x element, all with category=TYPE_REFERENCE:
        RR_TOF: implementation-data-type=uint16
        RR_Sensor_Status_{0..7}: implementation-data-type=boolean
        RR_CRC: implementation-data-type=uint8
        RR_Ringtime: implementation-data-type=uint8
    MsgGr_LIN2_MasterReq
      8 x element, all with category=TYPE_REFERENCE, implementation-data-type=uint8:
        MasterReqB{0..7}
    MsgGr_LIN2_SlaveResp
      8 x element, all with category=TYPE_REFERENCE, implementation-data-type=uint8:
        SlaveRespB{0..7}
package /LIN2/SYSSIGNALS
  16 x system signal:
    SystemSignal_LIN2_MasterReq_MasterReqB{0..7}
    SystemSignal_LIN2_SlaveResp_SlaveRespB{0..7}
package /LIN2/ISIGNALS
  16 x i signal, all with length=8:
    ISignal_LIN2_MasterReq_MasterReqB0: init-value=128, system-signal=SystemSignal_LIN2_MasterReq_MasterReqB0
    ISignal_LIN2_MasterReq_MasterReqB{1..7}: init-value=0, system-signal=SystemSignal_LIN2_MasterReq_MasterReqB{1..7}
    ISignal_LIN2_SlaveResp_SlaveRespB0: init-value=128, system-signal=SystemSignal_LIN2_SlaveResp_SlaveRespB0
    ISignal_LIN2_SlaveResp_SlaveRespB{1..7}: init-value=0, system-signal=SystemSignal_LIN2_SlaveResp_SlaveRespB{1..7}
package /LIN2/LINTP
  lin tp config LinTpConfig
    tp-connections:
      data-pdu=NPdu_LIN2_MasterReq, flow-control=NPdu_LIN2_SlaveResp, lin-tp-n-sdu=DcmIPdu_LIN2_MasterReq
      data-pdu=NPdu_LIN2_SlaveResp, flow-control=NPdu_LIN2_MasterReq, lin-tp-n-sdu=DcmIPdu_LIN2_SlaveResp
    lin tp node ECU1: connector=Conn_ECU1_LIN2
package /LIN2/INTERFACES
  11 x sender receiver interface:
    Gr_MsgGr_LIN2_Master_Cmd
      data MsgGr_LIN2_Master_Cmd: type=MsgGr_LIN2_Master_Cmd, init-value=fields=[255, 3, 0, 0, 0, 0, 0, 0, 0, 0, 0, 0, 0, 0, 0, 0, 0, 0, 0]
    Gr_MsgGr_LIN2_FL_Sensor_Status
      data MsgGr_LIN2_FL_Sensor_Status: type=MsgGr_LIN2_FL_Sensor_Status, init-value=fields=[0, 0, 0, 0, 0, 0, 0, 0, 0, 0, 0]
    Gr_MsgGr_LIN2_FCL_Sensor_Status
      data MsgGr_LIN2_FCL_Sensor_Status: type=MsgGr_LIN2_FCL_Sensor_Status, init-value=fields=[0, 0, 0, 0, 0, 0, 0, 0, 0, 0, 0]
    Gr_MsgGr_LIN2_FCR_Sensor_Status
      data MsgGr_LIN2_FCR_Sensor_Status: type=MsgGr_LIN2_FCR_Sensor_Status, init-value=fields=[0, 0, 0, 0, 0, 0, 0, 0, 0, 0, 0]
    Gr_MsgGr_LIN2_FR_Sensor_Status
      data MsgGr_LIN2_FR_Sensor_Status: type=MsgGr_LIN2_FR_Sensor_Status, init-value=fields=[0, 0, 0, 0, 0, 0, 0, 0, 0, 0, 0]
    Gr_MsgGr_LIN2_RL_Sensor_Status
      data MsgGr_LIN2_RL_Sensor_Status: type=MsgGr_LIN2_RL_Sensor_Status, init-value=fields=[0, 0, 0, 0, 0, 0, 0, 0, 0, 0, 0]
    Gr_MsgGr_LIN2_RCL_Sensor_Status
      data MsgGr_LIN2_RCL_Sensor_Status: type=MsgGr_LIN2_RCL_Sensor_Status, init-value=fields=[0, 0, 0, 0, 0, 0, 0, 0, 0, 0, 0]
    Gr_MsgGr_LIN2_RCR_Sensor_Status
      data MsgGr_LIN2_RCR_Sensor_Status: type=MsgGr_LIN2_RCR_Sensor_Status, init-value=fields=[0, 0, 0, 0, 0, 0, 0, 0, 0, 0, 0]
    Gr_MsgGr_LIN2_RR_Sensor_Status
      data MsgGr_LIN2_RR_Sensor_Status: type=MsgGr_LIN2_RR_Sensor_Status, init-value=fields=[0, 0, 0, 0, 0, 0, 0, 0, 0, 0, 0]
    Gr_MsgGr_LIN2_MasterReq
      data MsgGr_LIN2_MasterReq: type=MsgGr_LIN2_MasterReq, init-value=fields=[128, 0, 0, 0, 0, 0, 0, 0]
    Gr_MsgGr_LIN2_SlaveResp
      data MsgGr_LIN2_SlaveResp: type=MsgGr_LIN2_SlaveResp, init-value=fields=[128, 0, 0, 0, 0, 0, 0, 0]
package /LIN2/ISIGNALGROUPS
  11 x i signal group:
    MsgGr_LIN2_Master_Cmd: i-signal=[ISignal_LIN2_Master_Cmd_NAD, ISignal_LIN2_Master_Cmd_PCI_Type, ISignal_LIN2_Master_Cmd_SID, ISignal_LIN2_Master_Cmd_RL_Sensor_Tx, ISignal_LIN2_Master_Cmd_RCL_Sensor_Tx, ISignal_LIN2_Master_Cmd_RCR_Sensor_Tx, ISignal_LIN2_Master_Cmd_RR_Sensor_Tx, ISignal_LIN2_Master_Cmd_FL_Sensor_Tx, ISignal_LIN2_Master_Cmd_FCL_Sensor_Tx, ISignal_LIN2_Master_Cmd_FCR_Sensor_Tx, ISignal_LIN2_Master_Cmd_FR_Sensor_Tx, ISignal_LIN2_Master_Cmd_RL_Sensor_Rx, ISignal_LIN2_Master_Cmd_RCL_Sensor_Rx, ISignal_LIN2_Master_Cmd_RCR_Sensor_Rx, ISignal_LIN2_Master_Cmd_RR_Sensor_Rx, ISignal_LIN2_Master_Cmd_FL_Sensor_Rx, ISignal_LIN2_Master_Cmd_FCL_Sensor_Rx, ISignal_LIN2_Master_Cmd_FCR_Sensor_Rx, ISignal_LIN2_Master_Cmd_FR_Sensor_Rx], system-signal-group=MsgGr_LIN2_Master_Cmd
    MsgGr_LIN2_FL_Sensor_Status: i-signal=[ISignal_LIN2_FL_Sensor_Status_FL_TOF, ISignal_LIN2_FL_Sensor_Status_FL_Sensor_Status_0, ISignal_LIN2_FL_Sensor_Status_FL_Sensor_Status_1, ISignal_LIN2_FL_Sensor_Status_FL_Sensor_Status_2, ISignal_LIN2_FL_Sensor_Status_FL_Sensor_Status_3, ISignal_LIN2_FL_Sensor_Status_FL_Sensor_Status_4, ISignal_LIN2_FL_Sensor_Status_FL_Sensor_Status_5, ISignal_LIN2_FL_Sensor_Status_FL_Sensor_Status_6, ISignal_LIN2_FL_Sensor_Status_FL_Sensor_Status_7, ISignal_LIN2_FL_Sensor_Status_FL_CRC, ISignal_LIN2_FL_Sensor_Status_FL_Ringtime], system-signal-group=MsgGr_LIN2_FL_Sensor_Status
    MsgGr_LIN2_FCL_Sensor_Status: i-signal=[ISignal_LIN2_FCL_Sensor_Status_FCL_TOF, ISignal_LIN2_FCL_Sensor_Status_FCL_Sensor_Status_0, ISignal_LIN2_FCL_Sensor_Status_FCL_Sensor_Status_1, ISignal_LIN2_FCL_Sensor_Status_FCL_Sensor_Status_2, ISignal_LIN2_FCL_Sensor_Status_FCL_Sensor_Status_3, ISignal_LIN2_FCL_Sensor_Status_FCL_Sensor_Status_4, ISignal_LIN2_FCL_Sensor_Status_FCL_Sensor_Status_5, ISignal_LIN2_FCL_Sensor_Status_FCL_Sensor_Status_6, ISignal_LIN2_FCL_Sensor_Status_FCL_Sensor_Status_7, ISignal_LIN2_FCL_Sensor_Status_FCL_CRC, ISignal_LIN2_FCL_Sensor_Status_FCL_Ringtime], system-signal-group=MsgGr_LIN2_FCL_Sensor_Status
    MsgGr_LIN2_FCR_Sensor_Status: i-signal=[ISignal_LIN2_FCR_Sensor_Status_FCR_TOF, ISignal_LIN2_FCR_Sensor_Status_FCR_Sensor_Status_0, ISignal_LIN2_FCR_Sensor_Status_FCR_Sensor_Status_1, ISignal_LIN2_FCR_Sensor_Status_FCR_Sensor_Status_2, ISignal_LIN2_FCR_Sensor_Status_FCR_Sensor_Status_3, ISignal_LIN2_FCR_Sensor_Status_FCR_Sensor_Status_4, ISignal_LIN2_FCR_Sensor_Status_FCR_Sensor_Status_5, ISignal_LIN2_FCR_Sensor_Status_FCR_Sensor_Status_6, ISignal_LIN2_FCR_Sensor_Status_FCR_Sensor_Status_7, ISignal_LIN2_FCR_Sensor_Status_FCR_CRC, ISignal_LIN2_FCR_Sensor_Status_FCR_Ringtime], system-signal-group=MsgGr_LIN2_FCR_Sensor_Status
    MsgGr_LIN2_FR_Sensor_Status: i-signal=[ISignal_LIN2_FR_Sensor_Status_FR_TOF, ISignal_LIN2_FR_Sensor_Status_FR_Sensor_Status_0, ISignal_LIN2_FR_Sensor_Status_FR_Sensor_Status_1, ISignal_LIN2_FR_Sensor_Status_FR_Sensor_Status_2, ISignal_LIN2_FR_Sensor_Status_FR_Sensor_Status_3, ISignal_LIN2_FR_Sensor_Status_FR_Sensor_Status_4, ISignal_LIN2_FR_Sensor_Status_FR_Sensor_Status_5, ISignal_LIN2_FR_Sensor_Status_FR_Sensor_Status_6, ISignal_LIN2_FR_Sensor_Status_FR_Sensor_Status_7, ISignal_LIN2_FR_Sensor_Status_FR_CRC, ISignal_LIN2_FR_Sensor_Status_FR_Ringtime], system-signal-group=MsgGr_LIN2_FR_Sensor_Status
    MsgGr_LIN2_RL_Sensor_Status: i-signal=[ISignal_LIN2_RL_Sensor_Status_RL_TOF, ISignal_LIN2_RL_Sensor_Status_RL_Sensor_Status_0, ISignal_LIN2_RL_Sensor_Status_RL_Sensor_Status_1, ISignal_LIN2_RL_Sensor_Status_RL_Sensor_Status_2, ISignal_LIN2_RL_Sensor_Status_RL_Sensor_Status_3, ISignal_LIN2_RL_Sensor_Status_RL_Sensor_Status_4, ISignal_LIN2_RL_Sensor_Status_RL_Sensor_Status_5, ISignal_LIN2_RL_Sensor_Status_RL_Sensor_Status_6, ISignal_LIN2_RL_Sensor_Status_RL_Sensor_Status_7, ISignal_LIN2_RL_Sensor_Status_RL_CRC, ISignal_LIN2_RL_Sensor_Status_RL_Ringtime], system-signal-group=MsgGr_LIN2_RL_Sensor_Status
    MsgGr_LIN2_RCL_Sensor_Status: i-signal=[ISignal_LIN2_RCL_Sensor_Status_RCL_TOF, ISignal_LIN2_RCL_Sensor_Status_RCL_Sensor_Status_0, ISignal_LIN2_RCL_Sensor_Status_RCL_Sensor_Status_1, ISignal_LIN2_RCL_Sensor_Status_RCL_Sensor_Status_2, ISignal_LIN2_RCL_Sensor_Status_RCL_Sensor_Status_3, ISignal_LIN2_RCL_Sensor_Status_RCL_Sensor_Status_4, ISignal_LIN2_RCL_Sensor_Status_RCL_Sensor_Status_5, ISignal_LIN2_RCL_Sensor_Status_RCL_Sensor_Status_6, ISignal_LIN2_RCL_Sensor_Status_RCL_Sensor_Status_7, ISignal_LIN2_RCL_Sensor_Status_RCL_CRC, ISignal_LIN2_RCL_Sensor_Status_RCL_Ringtime], system-signal-group=MsgGr_LIN2_RCL_Sensor_Status
    MsgGr_LIN2_RCR_Sensor_Status: i-signal=[ISignal_LIN2_RCR_Sensor_Status_RCR_TOF, ISignal_LIN2_RCR_Sensor_Status_RCR_Sensor_Status_0, ISignal_LIN2_RCR_Sensor_Status_RCR_Sensor_Status_1, ISignal_LIN2_RCR_Sensor_Status_RCR_Sensor_Status_2, ISignal_LIN2_RCR_Sensor_Status_RCR_Sensor_Status_3, ISignal_LIN2_RCR_Sensor_Status_RCR_Sensor_Status_4, ISignal_LIN2_RCR_Sensor_Status_RCR_Sensor_Status_5, ISignal_LIN2_RCR_Sensor_Status_RCR_Sensor_Status_6, ISignal_LIN2_RCR_Sensor_Status_RCR_Sensor_Status_7, ISignal_LIN2_RCR_Sensor_Status_RCR_CRC, ISignal_LIN2_RCR_Sensor_Status_RCR_Ringtime], system-signal-group=MsgGr_LIN2_RCR_Sensor_Status
    MsgGr_LIN2_RR_Sensor_Status: i-signal=[ISignal_LIN2_RR_Sensor_Status_RR_TOF, ISignal_LIN2_RR_Sensor_Status_RR_Sensor_Status_0, ISignal_LIN2_RR_Sensor_Status_RR_Sensor_Status_1, ISignal_LIN2_RR_Sensor_Status_RR_Sensor_Status_2, ISignal_LIN2_RR_Sensor_Status_RR_Sensor_Status_3, ISignal_LIN2_RR_Sensor_Status_RR_Sensor_Status_4, ISignal_LIN2_RR_Sensor_Status_RR_Sensor_Status_5, ISignal_LIN2_RR_Sensor_Status_RR_Sensor_Status_6, ISignal_LIN2_RR_Sensor_Status_RR_Sensor_Status_7, ISignal_LIN2_RR_Sensor_Status_RR_CRC, ISignal_LIN2_RR_Sensor_Status_RR_Ringtime], system-signal-group=MsgGr_LIN2_RR_Sensor_Status
    MsgGr_LIN2_MasterReq: i-signal=[ISignal_LIN2_MasterReq_MasterReqB0, ISignal_LIN2_MasterReq_MasterReqB1, ISignal_LIN2_MasterReq_MasterReqB2, ISignal_LIN2_MasterReq_MasterReqB3, ISignal_LIN2_MasterReq_MasterReqB4, ISignal_LIN2_MasterReq_MasterReqB5, ISignal_LIN2_MasterReq_MasterReqB6, ISignal_LIN2_MasterReq_MasterReqB7], system-signal-group=MsgGr_LIN2_MasterReq
    MsgGr_LIN2_SlaveResp: i-signal=[ISignal_LIN2_SlaveResp_SlaveRespB0, ISignal_LIN2_SlaveResp_SlaveRespB1, ISignal_LIN2_SlaveResp_SlaveRespB2, ISignal_LIN2_SlaveResp_SlaveRespB3, ISignal_LIN2_SlaveResp_SlaveRespB4, ISignal_LIN2_SlaveResp_SlaveRespB5, ISignal_LIN2_SlaveResp_SlaveRespB6, ISignal_LIN2_SlaveResp_SlaveRespB7], system-signal-group=MsgGr_LIN2_SlaveResp
